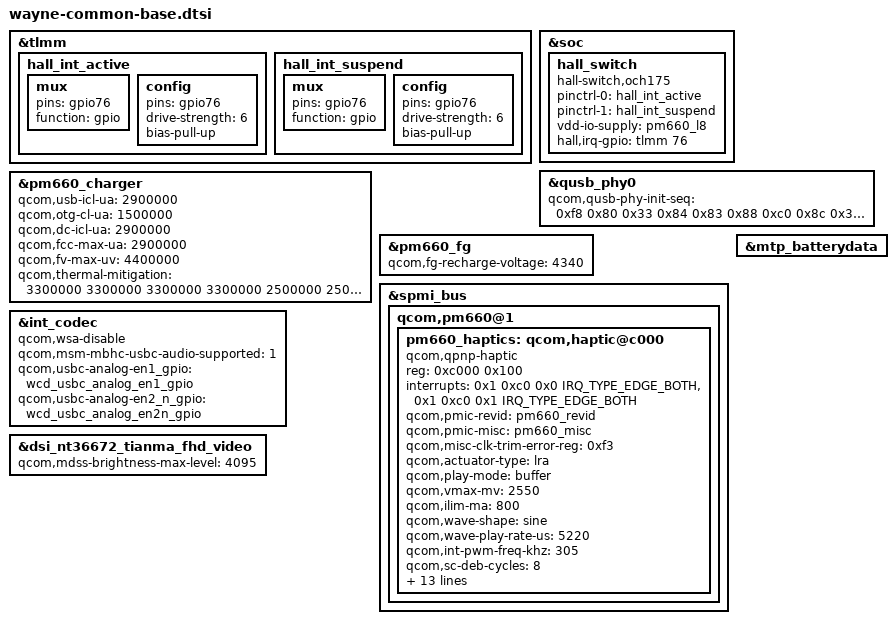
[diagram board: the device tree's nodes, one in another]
// SPDX-License-Identifier: GPL-2.0-only

#include "wayne-camera-sensor-mtp.dtsi"

/* Common between jasmine and wayne */
&tlmm {
	hall_int_active:hall_int_active {
		mux {
			pins = "gpio76";
			function = "gpio";
		};

		config {
			pins = "gpio76";
			drive-strength = <6>;
			bias-pull-up;
		};
	};

	hall_int_suspend: hall_int_suspend {
		mux {
			pins = "gpio76";
			function = "gpio";
		};

		config {
			pins = "gpio76";
			drive-strength = <6>;
			bias-pull-up;
		};
	};
};

&soc {
	hall_switch {
		compatible = "hall-switch,och175";
		pinctrl-names = "hall_active","hall_suspend";
		pinctrl-0 = <&hall_int_active>;
		pinctrl-1 = <&hall_int_suspend>;
		vdd-io-supply= <&pm660_l8>;
		interrupt-names = "hall_irq";
		hall,irq-gpio = <&tlmm 76 0x0>;
	};
};

/* sdm660-common.dtsi diff wayne - whyred/tulip */
&qusb_phy0 {
	qcom,qusb-phy-init-seq = <
		0xf8 0x80
		0x33 0x84
		0x83 0x88
		0xc0 0x8c
		0x30 0x08
		0x79 0x0c
		0x21 0x10
		0x14 0x9c
		0x9f 0x1c
		0x00 0x18
	>;
};

&pm660_charger {
	qcom,usb-icl-ua = <2900000>;
	qcom,otg-cl-ua = <1500000>;
	qcom,dc-icl-ua = <2900000>;
	qcom,fcc-max-ua = <2900000>;
	qcom,fv-max-uv = <4400000>;
	qcom,thermal-mitigation = <3300000 3300000 3300000 3300000 2500000 2500000 2100000>;
};

&pm660_fg {
	qcom,fg-recharge-voltage = <4340>;
};

&spmi_bus {
	qcom,pm660@1 {
		/delete-node/ qcom,haptic@c000;
		pm660_haptics: qcom,haptic@c000 {
			compatible = "qcom,qpnp-haptic";
			reg = <0xc000 0x100>;
			interrupts = <0x1 0xc0 0x0 IRQ_TYPE_EDGE_BOTH>,
				     <0x1 0xc0 0x1 IRQ_TYPE_EDGE_BOTH>;
			interrupt-names = "sc-irq", "play-irq";
			qcom,pmic-revid = <&pm660_revid>;
			qcom,pmic-misc = <&pm660_misc>;
			qcom,misc-clk-trim-error-reg = <0xf3>;
			qcom,actuator-type = "lra";
			qcom,play-mode = "buffer";
			qcom,vmax-mv = <2550>;
			qcom,ilim-ma = <800>;
			qcom,wave-shape = "sine";
			qcom,wave-play-rate-us = <5220>;
			qcom,int-pwm-freq-khz = <305>;
			qcom,sc-deb-cycles = <8>;
			qcom,en-brake;
			qcom,brake-pattern = [02 02 01 00];
			qcom,wave-samples = [3e 3e 3e 00 00 00 00 00];
			qcom,wave-samples-two = [3e 3e 3e 3e 00 00 00 00];
			qcom,wave-samples-three = [3e 3e 3e 3e 3e 00 00 00];
			qcom,wave-rep-cnt = <1>;
			qcom,wave-samp-rep-cnt = <1>;
			qcom,lra-high-z = "opt1";
			qcom,lra-auto-res-mode = "none";
			qcom,lra-calibrate-at-eop = <0>;
			qcom,lra-hw-auto-resonance;
		};
	};
};

/* msm-audio.dtsi wayne specific diff */
&int_codec {
	qcom,wsa-disable;
	/delete-property/ qcom,msm-micbias2-ext-cap;
	qcom,msm-mbhc-usbc-audio-supported = <1>;
	qcom,usbc-analog-en1_gpio = <&wcd_usbc_analog_en1_gpio>;
	qcom,usbc-analog-en2_n_gpio = <&wcd_usbc_analog_en2n_gpio>;
};

/* sdm660-mtp.dtsi wayne specific diff */
&mtp_batterydata {
	#include "fg-gen3-batterydata-l8866sun-3000mah.dtsi"
	#include "fg-gen3-batterydata-l8866cos-3000mah.dtsi"
	#include "fg-gen3-batterydata-l8866default-3000mah.dtsi"
};

&dsi_nt36672_tianma_fhd_video {
	qcom,mdss-brightness-max-level = <4095>;
};
